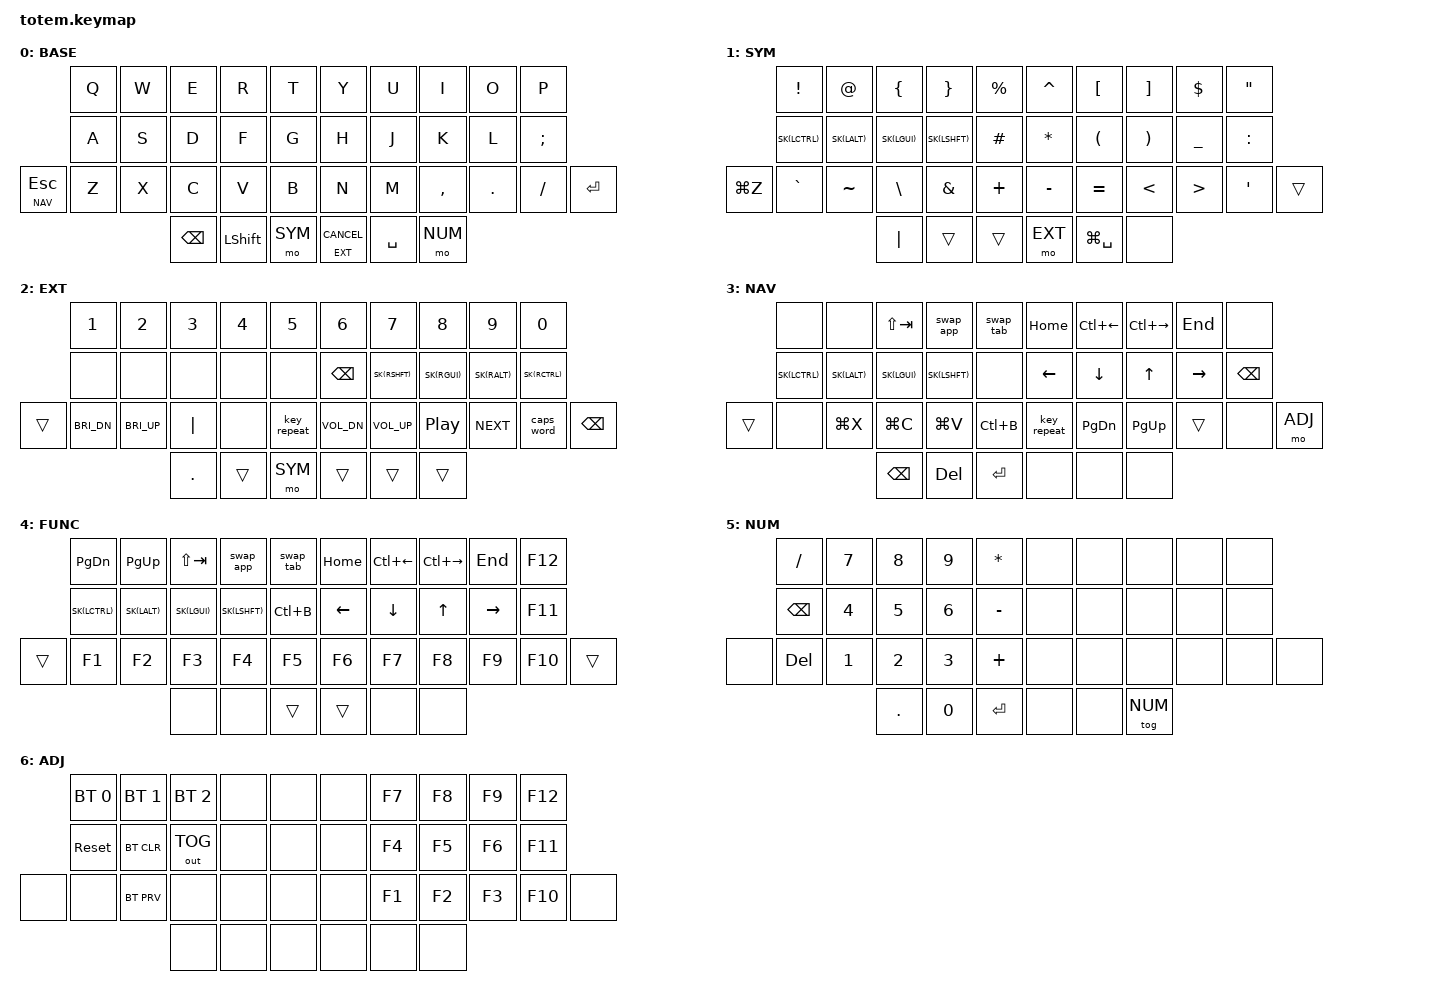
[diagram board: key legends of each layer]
//
//                                                        ▀▀▀▀▀     ▀▀▀▀▀          ▀▀█▀▀
//                                                        ▄▀▀▀▄  ▄  ▄▀▀▀▄  ▄  ▄▀▀▀▄  █  ▄▀▀▀▄
//                                                        █   █  █  █   █  █  █   █  █  █   █
//                                                         ▀▀▀   █   ▀▀▀   █   ▀▀▀   ▀   ▀▀▀
//                                                               █      ▄▄▄█▄▄▄    █   █
//                                                               ▀      █  █  █     █▄█
//                                                             ▀▀▀▀▀    █  █  █      ▀
//                                                                      ▀  ▀  ▀
//
// ▄▄▄▄▄▄▄▄▄▄▄▄▄▄▄▄▄▄▄▄▄▄▄▄▄▄▄▄▄▄▄▄▄▄▄▄▄▄▄▄▄▄▄▄▄▄▄▄▄▄▄▄▄▄▄▄▄▄▄▄▄▄▄▄▄▄▄▄▄▄▄▄▄▄▄▄▄▄▄▄▄▄▄▄▄▄▄▄▄▄▄▄▄▄▄▄▄▄▄▄▄▄▄▄▄▄▄▄▄▄▄▄▄▄▄▄▄▄▄▄▄▄▄▄▄▄▄▄▄▄▄▄▄▄▄▄▄▄▄▄▄▄▄▄▄▄▄▄▄


#include <behaviors.dtsi>
#include <dt-bindings/zmk/keys.h>
#include <dt-bindings/zmk/bt.h>
#include <dt-bindings/zmk/outputs.h>
#include "totem.h"

&mt {
  quick-tap-ms = <100>;
  global-quick-tap;
  flavor = "tap-preferred";
  tapping-term-ms = <170>;
};

&lt {
  flavor = "hold-preferred";
  tapping-term-ms = <170>;
};

&sk {
  release-after-ms = <1200>;
};

/ {
    conditional_layers {
        compatible = "zmk,conditional-layers";
        func_layer {
            if-layers = <SYM EXT>;
            then-layer = <FUNC>;
        };
    };


    behaviors {

        // Sticky key on tap, normal key on hold
        // Useful for modifier-clicking without the modifier remaining active
        nk: not_so_sticky_key {
          compatible = "zmk,behavior-hold-tap";
          label = "NOT_SO_STICKY_KEY";
          #binding-cells = <2>;
          tapping_term_ms = <400>;
          flavor = "tap-preferred";
          bindings = <&kp>, <&sk>;
        };

        // Swapper for CMD+TAB (app switching). Holds GUI while tapping TAB;
        // the reverse key (SHIFT+TAB) is ignored here so it can tap in the
        // other direction without releasing GUI.
        swap_app: swap_app {
          compatible = "zmk,behavior-tri-state";
          #binding-cells = <0>;
          bindings = <&kt LGUI>, <&kp TAB>, <&kt LGUI>;
          ignored-key-positions = <2 12 13>;
          ignored-layers = <NAV>;
          timeout-ms = <6000>;
        };

        // Swapper for CTRL+TAB (tab switching)
        swap_tab: swap_tab {
          compatible = "zmk,behavior-tri-state";
          #binding-cells = <0>;
          bindings = <&kt LCTRL>, <&kp TAB>, <&kt LCTRL>;
          ignored-key-positions = <12 13>;
          ignored-layers = <NAV>;
          timeout-ms = <6000>;
        };
  };

    combos {
            compatible = "zmk,combos";
            combo_esc {
                timeout-ms = <50>;
                key-positions = <11 12>;
                bindings = <&kp ESC>;
                layers = <BASE>;
            };
            combo_tab {
                timeout-ms = <50>;
                key-positions = <12 13>;
                bindings = <&kp TAB>;
                layers = <BASE NUM>;
            };
            combo_enter {
                timeout-ms = <50>;
                key-positions = <17 18>;
                bindings = <&kp RET>;
                layers = <BASE NUM>;
            };
            combo_bspc {
                timeout-ms = <50>;
                key-positions = <16 17>;
                bindings = <&kp BSPC>;
                layers = <BASE NUM>;
            };
            combo_pipe {
                timeout-ms = <50>;
                key-positions = <22 23>;
                bindings = <&kp PIPE>;
                layers = <SYM>;
            };
            combo_num {
                timeout-ms = <50>;
                key-positions = <21 22>;
                bindings = <&tog NUM>;
                layers = <BASE NUM>;
            };
            combo_mute {
                timeout-ms = <50>;
                key-positions = <26 27>;
                bindings = <&kp C_MUTE>;
                layers = <EXT>;
            };
            combo_play_pause {
                timeout-ms = <50>;
                key-positions = <28 29>;
                bindings = <&kp C_PREV>;
                layers = <EXT>;
            };
            combo_tmux {
                timeout-ms = <50>;
                key-positions = <24 25>;
                bindings = <&kp LC(B)>;
                layers = <BASE>;
            };
    };


        keymap {
                compatible = "zmk,keymap";
// ▄▄▄▄▄▄▄▄▄▄▄▄▄▄▄▄▄▄▄▄▄▄▄▄▄▄▄▄▄▄▄▄▄▄▄▄▄▄▄▄▄▄▄▄▄▄▄▄▄▄▄▄▄▄▄▄▄▄▄▄▄▄▄▄▄▄▄▄▄▄▄▄▄▄▄▄▄▄▄▄▄▄▄▄▄▄▄▄▄▄▄▄▄▄▄▄▄▄▄▄▄▄▄▄▄▄▄▄▄▄▄▄▄▄▄▄▄▄▄▄▄▄▄▄▄▄▄▄▄▄▄▄▄▄▄▄▄▄▄▄▄▄▄▄▄▄▄▄▄

                base_layer {
// ┏━━━━━━━━━━━━━━━━━━━━━━━━━━━━━━━━━━━━━━━┓
label= "BASE"                              ;
// ┗━━━━━━━━━━━━━━━━━━━━━━━━━━━━━━━━━━━━━━━┛
//             ┏━━━━━━━━━━━┳━━━━━━━━━━━┳━━━━━━━━━━━┳━━━━━━━━━━━┳━━━━━━━━━━━┓   ┏━━━━━━━━━━━┳━━━━━━━━━━━┳━━━━━━━━━━━┳━━━━━━━━━━━┳━━━━━━━━━━━┓
//             ┃     Q     ┃     W     ┃     E     ┃     R     ┃     T     ┃   ┃     Y     ┃     U     ┃     I     ┃     O     ┃     P     ┃
//             ┣━━━━━━━━━━━╋━━━━━━━━━━━╋━━━━━━━━━━━╋━━━━━━━━━━━╋━━━━━━━━━━━┫   ┣━━━━━━━━━━━╋━━━━━━━━━━━╋━━━━━━━━━━━╋━━━━━━━━━━━╋━━━━━━━━━━━┫
//             ┃     A     ┃     S     ┃     D     ┃     F     ┃     G     ┃   ┃     H     ┃     J     ┃     K     ┃     L     ┃     ;     ┃
// ┏━━━━━━━━━━━╋━━━━━━━━━━━╋━━━━━━━━━━━╋━━━━━━━━━━━╋━━━━━━━━━━━╋━━━━━━━━━━━┫   ┣━━━━━━━━━━━╋━━━━━━━━━━━╋━━━━━━━━━━━╋━━━━━━━━━━━╋━━━━━━━━━━━╋━━━━━━━━━━━┓
// ┃           ┃     Z     ┃     X     ┃     C     ┃     V     ┃     B     ┃   ┃     N     ┃     M     ┃     ,     ┃     .     ┃     /     ┃   ENTER   ┃
// ┗━━━━━━━━━━━┻━━━━━━━━━━━┻━━━━━━━━━━━╋━━━━━━━━━━━╋━━━━━━━━━━━╋━━━━━━━━━━━┫   ┣━━━━━━━━━━━╋━━━━━━━━━━━╋━━━━━━━━━━━╋━━━━━━━━━━━┻━━━━━━━━━━━┻━━━━━━━━━━━┛
//                                     ┃    BSPC   ┃    SFT    ┃    SPC    ┃   ┃   ENTER   ┃    SPC    ┃           ┃
//                                     ┗━━━━━━━━━━━┻━━━━━━━━━━━┻━━━━━━━━━━━┛   ┗━━━━━━━━━━━┻━━━━━━━━━━━┻━━━━━━━━━━━┛
 bindings = <
// ╷           ╷           ╷           ╷           ╷           ╷           ╷   ╷           ╷           ╷           ╷           ╷           ╷           ╷

                &kp Q       &kp W       &kp E       &kp R       &kp T           &kp Y       &kp U       &kp I       &kp O       &kp P
                &kp A       &kp S       &kp D       &kp F       &kp G           &kp H       &kp J       &kp K       &kp L       &kp SEMI
    &lt NAV ESC &kp Z       &kp X       &kp C       &kp V       &kp B           &kp N       &kp M       &kp COMMA   &kp DOT     &kp FSLH    &kp RET
                                        &kp BSPC    &kp LSHFT   &mo SYM         &lt EXT K_CANCEL &kp SPACE   &mo NUM
                        >;
                };

// ▄▄▄▄▄▄▄▄▄▄▄▄▄▄▄▄▄▄▄▄▄▄▄▄▄▄▄▄▄▄▄▄▄▄▄▄▄▄▄▄▄▄▄▄▄▄▄▄▄▄▄▄▄▄▄▄▄▄▄▄▄▄▄▄▄▄▄▄▄▄▄▄▄▄▄▄▄▄▄▄▄▄▄▄▄▄▄▄▄▄▄▄▄▄▄▄▄▄▄▄▄▄▄▄▄▄▄▄▄▄▄▄▄▄▄▄▄▄▄▄▄▄▄▄▄▄▄▄▄▄▄▄▄▄▄▄▄▄▄▄▄▄▄▄▄▄▄▄▄

                sym_layer {
// ┏━━━━━━━━━━━━━━━━━━━━━━━━━━━━━━━━━━━━━━━┓
label= "SYM"                               ;
// ┗━━━━━━━━━━━━━━━━━━━━━━━━━━━━━━━━━━━━━━━┛
//             ┏━━━━━━━━━━━┳━━━━━━━━━━━┳━━━━━━━━━━━┳━━━━━━━━━━━┳━━━━━━━━━━━┓   ┏━━━━━━━━━━━┳━━━━━━━━━━━┳━━━━━━━━━━━┳━━━━━━━━━━━┳━━━━━━━━━━━┓
//             ┃     !     ┃     @     ┃     {     ┃     }     ┃     %     ┃   ┃     ^     ┃     [     ┃     ]     ┃     $     ┃     "     ┃
//             ┣━━━━━━━━━━━╋━━━━━━━━━━━╋━━━━━━━━━━━╋━━━━━━━━━━━╋━━━━━━━━━━━┫   ┣━━━━━━━━━━━╋━━━━━━━━━━━╋━━━━━━━━━━━╋━━━━━━━━━━━╋━━━━━━━━━━━┫
//             ┃  OS_CTL   ┃  OS_ALT   ┃  OS_CMD   ┃  OS_SFT   ┃     #     ┃   ┃     *     ┃     (     ┃     )     ┃     _     ┃     :     ┃
// ┏━━━━━━━━━━━╋━━━━━━━━━━━╋━━━━━━━━━━━╋━━━━━━━━━━━╋━━━━━━━━━━━╋━━━━━━━━━━━┫   ┣━━━━━━━━━━━╋━━━━━━━━━━━╋━━━━━━━━━━━╋━━━━━━━━━━━╋━━━━━━━━━━━╋━━━━━━━━━━━┓
// ┃   CMD Z   ┃     `     ┃     ~     ┃     \     ┃     &     ┃     +     ┃   ┃     -     ┃     =     ┃     <     ┃     >     ┃     '     ┃           ┃
// ┗━━━━━━━━━━━┻━━━━━━━━━━━┻━━━━━━━━━━━╋━━━━━━━━━━━╋━━━━━━━━━━━╋━━━━━━━━━━━┫   ┣━━━━━━━━━━━╋━━━━━━━━━━━╋━━━━━━━━━━━╋━━━━━━━━━━━┻━━━━━━━━━━━┻━━━━━━━━━━━┛
//                                     ┃    |      ┃           ┃    SYM    ┃   ┃    EXT    ┃           ┃           ┃
//                                     ┗━━━━━━━━━━━┻━━━━━━━━━━━┻━━━━━━━━━━━┛   ┗━━━━━━━━━━━┻━━━━━━━━━━━┻━━━━━━━━━━━┛
 bindings = <
// ╷           ╷           ╷           ╷           ╷           ╷           ╷   ╷           ╷           ╷           ╷           ╷           ╷           ╷

                &kp EXCL    &kp AT      &kp LBRC    &kp RBRC    &kp PRCNT       &kp CARET   &kp LBKT    &kp RBKT    &kp DLLR    &kp DQT
                SK(LCTRL)   SK(LALT)    SK(LGUI)    SK(LSHFT)   &kp HASH        &kp STAR    &kp LPAR    &kp RPAR    &kp UNDER   &kp COLON
    &kp LG(Z)   &kp GRAVE   &kp TILDE   &kp BSLH    &kp AMPS    &kp PLUS        &kp MINUS   &kp EQUAL   &kp LT      &kp GT      &kp SQT     &trans
                                        &kp PIPE    &trans      &trans          &mo EXT     &kp LG(SPACE) &none
                        >;
                };


// ▄▄▄▄▄▄▄▄▄▄▄▄▄▄▄▄▄▄▄▄▄▄▄▄▄▄▄▄▄▄▄▄▄▄▄▄▄▄▄▄▄▄▄▄▄▄▄▄▄▄▄▄▄▄▄▄▄▄▄▄▄▄▄▄▄▄▄▄▄▄▄▄▄▄▄▄▄▄▄▄▄▄▄▄▄▄▄▄▄▄▄▄▄▄▄▄▄▄▄▄▄▄▄▄▄▄▄▄▄▄▄▄▄▄▄▄▄▄▄▄▄▄▄▄▄▄▄▄▄▄▄▄▄▄▄▄▄▄▄▄▄▄▄▄▄▄▄▄▄

                ext_layer {
// ┏━━━━━━━━━━━━━━━━━━━━━━━━━━━━━━━━━━━━━━━┓
label= "EXT"                               ;
// ┗━━━━━━━━━━━━━━━━━━━━━━━━━━━━━━━━━━━━━━━┛
//             ┏━━━━━━━━━━━┳━━━━━━━━━━━┳━━━━━━━━━━━┳━━━━━━━━━━━┳━━━━━━━━━━━┓   ┏━━━━━━━━━━━┳━━━━━━━━━━━┳━━━━━━━━━━━┳━━━━━━━━━━━┳━━━━━━━━━━━┓
//             ┃     1     ┃     2     ┃     3     ┃     4     ┃     5     ┃   ┃     6     ┃     7     ┃     8     ┃     9     ┃     0     ┃
//             ┣━━━━━━━━━━━╋━━━━━━━━━━━╋━━━━━━━━━━━╋━━━━━━━━━━━╋━━━━━━━━━━━┫   ┣━━━━━━━━━━━╋━━━━━━━━━━━╋━━━━━━━━━━━╋━━━━━━━━━━━╋━━━━━━━━━━━┫
//             ┃           ┃           ┃           ┃           ┃           ┃   ┃   BSPC    ┃  OS_SFT   ┃  OS_CMD   ┃  OS_ALT   ┃  OS_CTL   ┃
// ┏━━━━━━━━━━━╋━━━━━━━━━━━╋━━━━━━━━━━━╋━━━━━━━━━━━╋━━━━━━━━━━━╋━━━━━━━━━━━┫   ┣━━━━━━━━━━━╋━━━━━━━━━━━╋━━━━━━━━━━━╋━━━━━━━━━━━╋━━━━━━━━━━━╋━━━━━━━━━━━┓
// ┃           ┃ BRI DW    ┃ BRI UP    ┃     |     ┃   REP     ┃           ┃   ┃   VOL DO  ┃  VOL UP   ┃   PREV    ┃   NEXT    ┃ CAP_WORD  ┃           ┃
// ┗━━━━━━━━━━━┻━━━━━━━━━━━┻━━━━━━━━━━━╋━━━━━━━━━━━╋━━━━━━━━━━━╋━━━━━━━━━━━┫   ┣━━━━━━━━━━━╋━━━━━━━━━━━╋━━━━━━━━━━━╋━━━━━━━━━━━┻━━━━━━━━━━━┻━━━━━━━━━━━┛
//                                     ┃     .     ┃           ┃    SYM    ┃   ┃    EXT    ┃           ┃           ┃
//                                     ┗━━━━━━━━━━━┻━━━━━━━━━━━┻━━━━━━━━━━━┛   ┗━━━━━━━━━━━┻━━━━━━━━━━━┻━━━━━━━━━━━┛
 bindings = <
// ╷           ╷           ╷           ╷           ╷           ╷           ╷   ╷           ╷           ╷           ╷           ╷           ╷           ╷

                &kp N1      &kp N2      &kp N3      &kp N4      &kp N5          &kp N6      &kp N7      &kp N8      &kp N9      &kp N0
                &none       &none       &none       &none       &none           &kp BSPC    SK(RSHFT)   SK(RGUI)    SK(RALT)    SK(RCTRL)
    &trans      &kp C_BRI_DN &kp C_BRI_UP &kp PIPE  &none       &key_repeat     &kp C_VOL_DN &kp C_VOL_UP &kp C_PP  &kp C_NEXT &caps_word  &kp BSPC
                                        &kp DOT     &trans      &mo SYM         &trans      &trans      &trans
                        >;
                };


// ▄▄▄▄▄▄▄▄▄▄▄▄▄▄▄▄▄▄▄▄▄▄▄▄▄▄▄▄▄▄▄▄▄▄▄▄▄▄▄▄▄▄▄▄▄▄▄▄▄▄▄▄▄▄▄▄▄▄▄▄▄▄▄▄▄▄▄▄▄▄▄▄▄▄▄▄▄▄▄▄▄▄▄▄▄▄▄▄▄▄▄▄▄▄▄▄▄▄▄▄▄▄▄▄▄▄▄▄▄▄▄▄▄▄▄▄▄▄▄▄▄▄▄▄▄▄▄▄▄▄▄▄▄▄▄▄▄▄▄▄▄▄▄▄▄▄▄▄▄

                nav_layer {
// ┏━━━━━━━━━━━━━━━━━━━━━━━━━━━━━━━━━━━━━━━┓
label= "NAV"                              ;
// ┗━━━━━━━━━━━━━━━━━━━━━━━━━━━━━━━━━━━━━━━┛
//             ┏━━━━━━━━━━━┳━━━━━━━━━━━┳━━━━━━━━━━━┳━━━━━━━━━━━┳━━━━━━━━━━━┓   ┏━━━━━━━━━━━┳━━━━━━━━━━━┳━━━━━━━━━━━┳━━━━━━━━━━━┳━━━━━━━━━━━┓
//             ┃           ┃           ┃  SW APP-  ┃  SW APP+  ┃  SW TAB   ┃   ┃   HOME    ┃  DSK PV   ┃  DSK NX   ┃    END    ┃           ┃
//             ┣━━━━━━━━━━━╋━━━━━━━━━━━╋━━━━━━━━━━━╋━━━━━━━━━━━╋━━━━━━━━━━━┫   ┣━━━━━━━━━━━╋━━━━━━━━━━━╋━━━━━━━━━━━╋━━━━━━━━━━━╋━━━━━━━━━━━┫
//             ┃  OS_CTL   ┃  OS_ALT   ┃  OS_CMD   ┃  OS_SFT   ┃           ┃   ┃   LEFT    ┃   DOWN    ┃    UP     ┃   RIGHT   ┃   BSPC    ┃
// ┏━━━━━━━━━━━╋━━━━━━━━━━━╋━━━━━━━━━━━╋━━━━━━━━━━━╋━━━━━━━━━━━╋━━━━━━━━━━━┫   ┣━━━━━━━━━━━╋━━━━━━━━━━━╋━━━━━━━━━━━╋━━━━━━━━━━━╋━━━━━━━━━━━╋━━━━━━━━━━━┓
// ┃           ┃           ┃    CUT    ┃   COPY    ┃   PASTE   ┃   CTL B   ┃   ┃   REP     ┃  PG DOWN  ┃   PG UP   ┃           ┃           ┃           ┃
// ┗━━━━━━━━━━━┻━━━━━━━━━━━┻━━━━━━━━━━━╋━━━━━━━━━━━╋━━━━━━━━━━━╋━━━━━━━━━━━┫   ┣━━━━━━━━━━━╋━━━━━━━━━━━╋━━━━━━━━━━━╋━━━━━━━━━━━┻━━━━━━━━━━━┻━━━━━━━━━━━┛
//                                     ┃   BSPC    |   DEL     ┃   ENTER   ┃   ┃           ┃           ┃           ┃
//                                     ┗━━━━━━━━━━━┻━━━━━━━━━━━┻━━━━━━━━━━━┛   ┗━━━━━━━━━━━┻━━━━━━━━━━━┻━━━━━━━━━━━┛
 bindings = <
// ╷           ╷           ╷           ╷           ╷           ╷           ╷   ╷           ╷           ╷           ╷           ╷           ╷           ╷

                &none       &none       &kp LS(TAB) &swap_app   &swap_tab       &kp HOME    &kp LC(LEFT) &kp LC(RIGHT) &kp END   &none
                SK(LCTRL)   SK(LALT)    SK(LGUI)    SK(LSHFT)   &none           &kp LEFT    &kp DOWN    &kp UP      &kp RIGHT   &kp BSPC
    &trans      &none       &kp LG(X)   &kp LG(C)   &kp LG(V)   &kp LC(B)       &key_repeat &kp PG_DN   &kp PG_UP   &trans      &none       &mo ADJ
                                        &kp BSPC    &kp DEL     &kp RET         &none       &none       &none
                        >;
                };

// ▄▄▄▄▄▄▄▄▄▄▄▄▄▄▄▄▄▄▄▄▄▄▄▄▄▄▄▄▄▄▄▄▄▄▄▄▄▄▄▄▄▄▄▄▄▄▄▄▄▄▄▄▄▄▄▄▄▄▄▄▄▄▄▄▄▄▄▄▄▄▄▄▄▄▄▄▄▄▄▄▄▄▄▄▄▄▄▄▄▄▄▄▄▄▄▄▄▄▄▄▄▄▄▄▄▄▄▄▄▄▄▄▄▄▄▄▄▄▄▄▄▄▄▄▄▄▄▄▄▄▄▄▄▄▄▄▄▄▄▄▄▄▄▄▄▄▄▄▄


                func_layer {
// ┏━━━━━━━━━━━━━━━━━━━━━━━━━━━━━━━━━━━━━━━┓
label= "FUNC"                              ;
// ┗━━━━━━━━━━━━━━━━━━━━━━━━━━━━━━━━━━━━━━━┛
//             ┏━━━━━━━━━━━┳━━━━━━━━━━━┳━━━━━━━━━━━┳━━━━━━━━━━━┳━━━━━━━━━━━┓   ┏━━━━━━━━━━━┳━━━━━━━━━━━┳━━━━━━━━━━━┳━━━━━━━━━━━┳━━━━━━━━━━━┓
//             ┃  PG DOWN  ┃  PG UP    ┃  SW APP-  ┃  SW APP+  ┃  SW TAB   ┃   ┃   HOME    ┃  DSK PV   ┃  DSK NX   ┃   END     ┃    F12    ┃
//             ┣━━━━━━━━━━━╋━━━━━━━━━━━╋━━━━━━━━━━━╋━━━━━━━━━━━╋━━━━━━━━━━━┫   ┣━━━━━━━━━━━╋━━━━━━━━━━━╋━━━━━━━━━━━╋━━━━━━━━━━━╋━━━━━━━━━━━┫
//             ┃  OS_CTL   ┃  OS_ALT   ┃  OS_CMD   ┃  OS_SFT   ┃  CTL B    ┃   ┃   LEFT    ┃    DOWN   ┃    UP     ┃   RIGHT   ┃    F11    ┃
// ┏━━━━━━━━━━━╋━━━━━━━━━━━╋━━━━━━━━━━━╋━━━━━━━━━━━╋━━━━━━━━━━━╋━━━━━━━━━━━┫   ┣━━━━━━━━━━━╋━━━━━━━━━━━╋━━━━━━━━━━━╋━━━━━━━━━━━╋━━━━━━━━━━━╋━━━━━━━━━━━┓
// ┃           ┃    F1     ┃    F2     ┃    F3     ┃    F4     ┃    F5     ┃   ┃    F6     ┃    F7     ┃    F8     ┃    F9     ┃    F10    ┃           ┃
// ┗━━━━━━━━━━━┻━━━━━━━━━━━┻━━━━━━━━━━━╋━━━━━━━━━━━╋━━━━━━━━━━━╋━━━━━━━━━━━┫   ┣━━━━━━━━━━━╋━━━━━━━━━━━╋━━━━━━━━━━━╋━━━━━━━━━━━┻━━━━━━━━━━━┻━━━━━━━━━━━┛
//                                     ┃           ┃           ┃           ┃   ┃           ┃           ┃           ┃
//                                     ┗━━━━━━━━━━━┻━━━━━━━━━━━┻━━━━━━━━━━━┛   ┗━━━━━━━━━━━┻━━━━━━━━━━━┻━━━━━━━━━━━┛
 bindings = <
// ╷           ╷           ╷           ╷           ╷           ╷           ╷   ╷           ╷           ╷           ╷           ╷           ╷           ╷

                &kp PG_DN   &kp PG_UP  &kp LS(TAB) &swap_app   &swap_tab       &kp HOME    &kp LC(LEFT) &kp LC(RIGHT) &kp END   &kp F12
                SK(LCTRL)   SK(LALT)   SK(LGUI)    SK(LSHFT)   &kp LC(B)       &kp LEFT    &kp DOWN     &kp UP      &kp RIGHT   &kp F11
    &trans      &kp F1      &kp F2     &kp F3      &kp F4      &kp F5          &kp F6      &kp F7       &kp F8      &kp F9      &kp F10     &trans
                                        &none      &none       &trans          &trans      &none       &none
                        >;
                };

// ▄▄▄▄▄▄▄▄▄▄▄▄▄▄▄▄▄▄▄▄▄▄▄▄▄▄▄▄▄▄▄▄▄▄▄▄▄▄▄▄▄▄▄▄▄▄▄▄▄▄▄▄▄▄▄▄▄▄▄▄▄▄▄▄▄▄▄▄▄▄▄▄▄▄▄▄▄▄▄▄▄▄▄▄▄▄▄▄▄▄▄▄▄▄▄▄▄▄▄▄▄▄▄▄▄▄▄▄▄▄▄▄▄▄▄▄▄▄▄▄▄▄▄▄▄▄▄▄▄▄▄▄▄▄▄▄▄▄▄▄▄▄▄▄▄▄▄▄▄


                num_layer {
// ┏━━━━━━━━━━━━━━━━━━━━━━━━━━━━━━━━━━━━━━━┓
label= "NUM"                               ;
// ┗━━━━━━━━━━━━━━━━━━━━━━━━━━━━━━━━━━━━━━━┛
//             ┏━━━━━━━━━━━┳━━━━━━━━━━━┳━━━━━━━━━━━┳━━━━━━━━━━━┳━━━━━━━━━━━┓   ┏━━━━━━━━━━━┳━━━━━━━━━━━┳━━━━━━━━━━━┳━━━━━━━━━━━┳━━━━━━━━━━━┓
//             ┃     /     ┃     9     ┃     8     ┃     7     ┃     *     ┃   ┃           ┃           ┃           ┃           ┃           ┃
//             ┣━━━━━━━━━━━╋━━━━━━━━━━━╋━━━━━━━━━━━╋━━━━━━━━━━━╋━━━━━━━━━━━┫   ┣━━━━━━━━━━━╋━━━━━━━━━━━╋━━━━━━━━━━━╋━━━━━━━━━━━╋━━━━━━━━━━━┫
//             ┃    BSPC   ┃     6     ┃     5     ┃     4     ┃     -     ┃   ┃           ┃           ┃           ┃           ┃           ┃
// ┏━━━━━━━━━━━╋━━━━━━━━━━━╋━━━━━━━━━━━╋━━━━━━━━━━━╋━━━━━━━━━━━╋━━━━━━━━━━━┫   ┣━━━━━━━━━━━╋━━━━━━━━━━━╋━━━━━━━━━━━╋━━━━━━━━━━━╋━━━━━━━━━━━╋━━━━━━━━━━━┓
// ┃           ┃    DEL    ┃     3     ┃     2     ┃     1     ┃     +     ┃   ┃           ┃           ┃           ┃           ┃           ┃           ┃
// ┗━━━━━━━━━━━┻━━━━━━━━━━━┻━━━━━━━━━━━╋━━━━━━━━━━━╋━━━━━━━━━━━╋━━━━━━━━━━━┫   ┣━━━━━━━━━━━╋━━━━━━━━━━━╋━━━━━━━━━━━╋━━━━━━━━━━━┻━━━━━━━━━━━┻━━━━━━━━━━━┛
//                                     ┃     .     ┃     0     ┃   ENT     ┃   ┃           ┃           ┃           ┃
//                                     ┗━━━━━━━━━━━┻━━━━━━━━━━━┻━━━━━━━━━━━┛   ┗━━━━━━━━━━━┻━━━━━━━━━━━┻━━━━━━━━━━━┛
 bindings = <
// ╷           ╷           ╷           ╷           ╷           ╷           ╷   ╷           ╷           ╷           ╷           ╷           ╷           ╷

                &kp FSLH    &kp N7      &kp N8      &kp N9      &kp STAR        &none       &none       &none       &none       &none
                &kp BSPC    &kp N4      &kp N5      &kp N6      &kp MINUS       &none       &none       &none       &none       &none
    &none       &kp DEL     &kp N1      &kp N2      &kp N3      &kp PLUS        &none       &none       &none       &none       &none       &none
                                        &kp DOT     &kp N0      &kp RET         &none       &none       &tog NUM
                        >;
                };

// ▄▄▄▄▄▄▄▄▄▄▄▄▄▄▄▄▄▄▄▄▄▄▄▄▄▄▄▄▄▄▄▄▄▄▄▄▄▄▄▄▄▄▄▄▄▄▄▄▄▄▄▄▄▄▄▄▄▄▄▄▄▄▄▄▄▄▄▄▄▄▄▄▄▄▄▄▄▄▄▄▄▄▄▄▄▄▄▄▄▄▄▄▄▄▄▄▄▄▄▄▄▄▄▄▄▄▄▄▄▄▄▄▄▄▄▄▄▄▄▄▄▄▄▄▄▄▄▄▄▄▄▄▄▄▄▄▄▄▄▄▄▄▄▄▄▄▄▄▄


                adjust_layer {
// ┏━━━━━━━━━━━━━━━━━━━━━━━━━━━━━━━━━━━━━━━┓
label= "ADJ"                               ;
// ┗━━━━━━━━━━━━━━━━━━━━━━━━━━━━━━━━━━━━━━━┛
//             ┏━━━━━━━━━━━┳━━━━━━━━━━━┳━━━━━━━━━━━┳━━━━━━━━━━━┳━━━━━━━━━━━┓   ┏━━━━━━━━━━━┳━━━━━━━━━━━┳━━━━━━━━━━━┳━━━━━━━━━━━┳━━━━━━━━━━━┓
//             ┃  BT SEL 0 ┃  BT SEL 1 ┃  BT SEL 2 ┃           ┃           ┃   ┃           ┃    F7     ┃    F8     ┃    F9     ┃    F12    ┃
//             ┣━━━━━━━━━━━╋━━━━━━━━━━━╋━━━━━━━━━━━╋━━━━━━━━━━━╋━━━━━━━━━━━┫   ┣━━━━━━━━━━━╋━━━━━━━━━━━╋━━━━━━━━━━━╋━━━━━━━━━━━╋━━━━━━━━━━━┫
//             ┃   RESET   ┃ BT CLEAR  ┃  OUT TOG  ┃           ┃           ┃   ┃           ┃    F4     ┃    F5     ┃    F6     ┃    F11    ┃
// ┏━━━━━━━━━━━╋━━━━━━━━━━━╋━━━━━━━━━━━╋━━━━━━━━━━━╋━━━━━━━━━━━╋━━━━━━━━━━━┫   ┣━━━━━━━━━━━╋━━━━━━━━━━━╋━━━━━━━━━━━╋━━━━━━━━━━━╋━━━━━━━━━━━╋━━━━━━━━━━━┓
// ┃           ┃           ┃  BT PRV   ┃           ┃           ┃           ┃   ┃           ┃    F1     ┃    F2     ┃    F3     ┃    F10    ┃           ┃
// ┗━━━━━━━━━━━┻━━━━━━━━━━━┻━━━━━━━━━━━╋━━━━━━━━━━━╋━━━━━━━━━━━╋━━━━━━━━━━━┫   ┣━━━━━━━━━━━╋━━━━━━━━━━━╋━━━━━━━━━━━╋━━━━━━━━━━━┻━━━━━━━━━━━┻━━━━━━━━━━━┛
//                                     ┃           ┃           ┃           ┃   ┃           ┃           ┃           ┃
//                                     ┗━━━━━━━━━━━┻━━━━━━━━━━━┻━━━━━━━━━━━┛   ┗━━━━━━━━━━━┻━━━━━━━━━━━┻━━━━━━━━━━━┛
 bindings = <
// ╷           ╷           ╷           ╷           ╷           ╷           ╷   ╷           ╷           ╷           ╷           ╷           ╷           ╷

                &bt BT_SEL 0 &bt BT_SEL 1 &bt BT_SEL 2 &none &none          &none      &kp F7      &kp F8      &kp F9      &kp F12
                &sys_reset &bt BT_CLR  &out OUT_TOG &none    &none          &none      &kp F4      &kp F5      &kp F6      &kp F11
    &none       &none      &bt BT_PRV  &none      &none      &none          &none      &kp F1      &kp F2      &kp F3      &kp F10     &none
                                       &none      &none      &none          &none      &none      &none
                        >;
                };
        };
};
